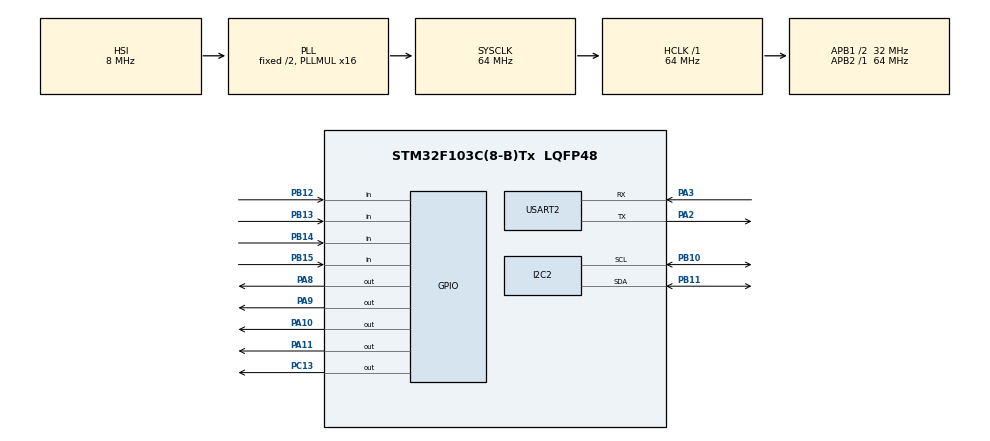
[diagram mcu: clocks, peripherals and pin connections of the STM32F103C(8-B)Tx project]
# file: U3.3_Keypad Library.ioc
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Mcu.Family=STM32F1
Mcu.Name=STM32F103C(8-B)Tx
Mcu.Package=LQFP48
NVIC.PriorityGroup=NVIC_PRIORITYGROUP_4
PA10.Signal=GPIO_Output
PA11.Signal=GPIO_Output
PA13.Mode=Serial_Wire
PA13.Signal=SYS_JTMS-SWDIO
PA14.Mode=Serial_Wire
PA14.Signal=SYS_JTCK-SWCLK
PA2.Mode=Asynchronous
PA2.Signal=USART2_TX
PA3.Mode=Asynchronous
PA3.Signal=USART2_RX
PA8.Signal=GPIO_Output
PA9.Signal=GPIO_Output
PB10.Mode=I2C
PB10.Signal=I2C2_SCL
PB11.Mode=I2C
PB11.Signal=I2C2_SDA
PB12.GPIO_PuPd=GPIO_PULLUP
PB12.Signal=GPIO_Input
PB13.GPIO_PuPd=GPIO_PULLUP
PB13.Signal=GPIO_Input
PB14.GPIO_PuPd=GPIO_PULLUP
PB14.Signal=GPIO_Input
PB15.GPIO_PuPd=GPIO_PULLUP
PB15.Signal=GPIO_Input
PC13-TAMPER-RTC.Signal=GPIO_Output
ProjectManager.HeapSize=0x200
ProjectManager.StackSize=0x400
ProjectManager.TargetToolchain=STM32CubeIDE
RCC.AHBFreq_Value=64000000
RCC.APB1CLKDivider=RCC_HCLK_DIV2
RCC.APB1Freq_Value=32000000
RCC.APB1TimFreq_Value=64000000
RCC.APB2Freq_Value=64000000
RCC.APB2TimFreq_Value=64000000
RCC.HCLKFreq_Value=64000000
RCC.PLLMUL=RCC_PLL_MUL16
RCC.SYSCLKFreq_VALUE=64000000
RCC.SYSCLKSource=RCC_SYSCLKSOURCE_PLLCLK
RCC.USBFreq_Value=64000000
USART2.VirtualMode=VM_ASYNC
board=custom

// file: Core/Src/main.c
/* USER CODE BEGIN Header */
/**
  ******************************************************************************
  * @file           : main.c
  * @brief          : Main program body
  ******************************************************************************
  * @attention
  *
  * Copyright (c) 2022 STMicroelectronics.
  * All rights reserved.
  *
  * This software is licensed under terms that can be found in the LICENSE file
  * in the root directory of this software component.
  * If no LICENSE file comes with this software, it is provided AS-IS.
  *
  ******************************************************************************
  */
/* USER CODE END Header */
#include "main.h"

/* USER CODE BEGIN Includes */

#include "keypad.h"

/* USER CODE END Includes */

I2C_HandleTypeDef hi2c2;

UART_HandleTypeDef huart2;

void SystemClock_Config(void);
static void MX_GPIO_Init(void);
static void MX_I2C2_Init(void);
static void MX_USART2_UART_Init(void);

/* USER CODE BEGIN 0 */

void KeypadPressingCallback(uint8_t key){
	uint8_t Tx_Buff[2] = {};
	sprintf((char *)Tx_Buff, "%c\n", key);
	HAL_UART_Transmit(&huart2, Tx_Buff, 2, 200);
}

/* USER CODE END 0 */

int main(void)
{

  /* MCU Configuration--------------------------------------------------------*/

  /* Reset of all peripherals, Initializes the Flash interface and the Systick. */
  HAL_Init();

  /* Configure the system clock */
  SystemClock_Config();

  /* Initialize all configured peripherals */
  MX_GPIO_Init();
  MX_I2C2_Init();
  MX_USART2_UART_Init();

  /* Infinite loop */
  while (1)
  {

    /* USER CODE BEGIN 3 */
	  Keypad_Handle();
  }
  /* USER CODE END 3 */
}

void SystemClock_Config(void)
{
  RCC_OscInitTypeDef RCC_OscInitStruct = {0};
  RCC_ClkInitTypeDef RCC_ClkInitStruct = {0};

  /** Initializes the RCC Oscillators according to the specified parameters
  * in the RCC_OscInitTypeDef structure.
  */
  RCC_OscInitStruct.OscillatorType = RCC_OSCILLATORTYPE_HSI;
  RCC_OscInitStruct.HSIState = RCC_HSI_ON;
  RCC_OscInitStruct.HSICalibrationValue = RCC_HSICALIBRATION_DEFAULT;
  RCC_OscInitStruct.PLL.PLLState = RCC_PLL_ON;
  RCC_OscInitStruct.PLL.PLLSource = RCC_PLLSOURCE_HSI_DIV2;
  RCC_OscInitStruct.PLL.PLLMUL = RCC_PLL_MUL16;
  if (HAL_RCC_OscConfig(&RCC_OscInitStruct) != HAL_OK)
  {
    Error_Handler();
  }
  /** Initializes the CPU, AHB and APB buses clocks
  */
  RCC_ClkInitStruct.ClockType = RCC_CLOCKTYPE_HCLK|RCC_CLOCKTYPE_SYSCLK
                              |RCC_CLOCKTYPE_PCLK1|RCC_CLOCKTYPE_PCLK2;
  RCC_ClkInitStruct.SYSCLKSource = RCC_SYSCLKSOURCE_PLLCLK;
  RCC_ClkInitStruct.AHBCLKDivider = RCC_SYSCLK_DIV1;
  RCC_ClkInitStruct.APB1CLKDivider = RCC_HCLK_DIV2;
  RCC_ClkInitStruct.APB2CLKDivider = RCC_HCLK_DIV1;

  if (HAL_RCC_ClockConfig(&RCC_ClkInitStruct, FLASH_LATENCY_2) != HAL_OK)
  {
    Error_Handler();
  }
}

static void MX_I2C2_Init(void)
{

  hi2c2.Instance = I2C2;
  hi2c2.Init.ClockSpeed = 100000;
  hi2c2.Init.DutyCycle = I2C_DUTYCYCLE_2;
  hi2c2.Init.OwnAddress1 = 0;
  hi2c2.Init.AddressingMode = I2C_ADDRESSINGMODE_7BIT;
  hi2c2.Init.DualAddressMode = I2C_DUALADDRESS_DISABLE;
  hi2c2.Init.OwnAddress2 = 0;
  hi2c2.Init.GeneralCallMode = I2C_GENERALCALL_DISABLE;
  hi2c2.Init.NoStretchMode = I2C_NOSTRETCH_DISABLE;
  if (HAL_I2C_Init(&hi2c2) != HAL_OK)
  {
    Error_Handler();
  }

}

static void MX_USART2_UART_Init(void)
{

  huart2.Instance = USART2;
  huart2.Init.BaudRate = 115200;
  huart2.Init.WordLength = UART_WORDLENGTH_8B;
  huart2.Init.StopBits = UART_STOPBITS_1;
  huart2.Init.Parity = UART_PARITY_NONE;
  huart2.Init.Mode = UART_MODE_TX_RX;
  huart2.Init.HwFlowCtl = UART_HWCONTROL_NONE;
  huart2.Init.OverSampling = UART_OVERSAMPLING_16;
  if (HAL_UART_Init(&huart2) != HAL_OK)
  {
    Error_Handler();
  }

}

static void MX_GPIO_Init(void)
{
  GPIO_InitTypeDef GPIO_InitStruct = {0};

  /* GPIO Ports Clock Enable */
  __HAL_RCC_GPIOC_CLK_ENABLE();
  __HAL_RCC_GPIOA_CLK_ENABLE();
  __HAL_RCC_GPIOB_CLK_ENABLE();

  /*Configure GPIO pin Output Level */
  HAL_GPIO_WritePin(GPIOC, GPIO_PIN_13, GPIO_PIN_RESET);

  /*Configure GPIO pin Output Level */
  HAL_GPIO_WritePin(GPIOA, GPIO_PIN_8|GPIO_PIN_9|GPIO_PIN_10|GPIO_PIN_11, GPIO_PIN_RESET);

  /*Configure GPIO pin : PC13 */
  GPIO_InitStruct.Pin = GPIO_PIN_13;
  GPIO_InitStruct.Mode = GPIO_MODE_OUTPUT_PP;
  GPIO_InitStruct.Pull = GPIO_NOPULL;
  GPIO_InitStruct.Speed = GPIO_SPEED_FREQ_LOW;
  HAL_GPIO_Init(GPIOC, &GPIO_InitStruct);

  /*Configure GPIO pins : PB12 PB13 PB14 PB15 */
  GPIO_InitStruct.Pin = GPIO_PIN_12|GPIO_PIN_13|GPIO_PIN_14|GPIO_PIN_15;
  GPIO_InitStruct.Mode = GPIO_MODE_INPUT;
  GPIO_InitStruct.Pull = GPIO_PULLUP;
  HAL_GPIO_Init(GPIOB, &GPIO_InitStruct);

  /*Configure GPIO pins : PA8 PA9 PA10 PA11 */
  GPIO_InitStruct.Pin = GPIO_PIN_8|GPIO_PIN_9|GPIO_PIN_10|GPIO_PIN_11;
  GPIO_InitStruct.Mode = GPIO_MODE_OUTPUT_PP;
  GPIO_InitStruct.Pull = GPIO_NOPULL;
  GPIO_InitStruct.Speed = GPIO_SPEED_FREQ_LOW;
  HAL_GPIO_Init(GPIOA, &GPIO_InitStruct);

}

void Error_Handler(void)
{
  __disable_irq();
  while (1)
  {
  }
}
